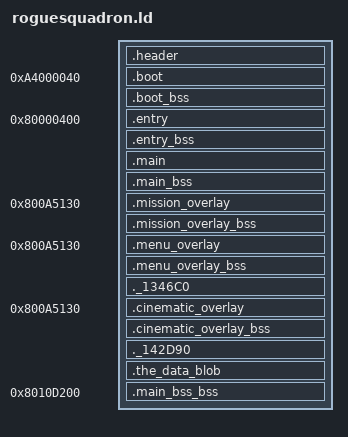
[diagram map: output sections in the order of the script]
SECTIONS
{
    __romPos = 0;
    header_ROM_START = __romPos;
    header_VRAM = ADDR(.header);
    .header : AT(header_ROM_START) SUBALIGN(16)
    {
        FILL(0x00000000);
        header_DATA_START = .;
        build/asm/header.o(.data);
        header_DATA_END = .;
        header_DATA_SIZE = ABSOLUTE(header_DATA_END - header_DATA_START);
    }
    __romPos += SIZEOF(.header);
    header_ROM_END = __romPos;
    header_VRAM_END = .;

    boot_ROM_START = __romPos;
    boot_VRAM = ADDR(.boot);
    .boot 0xA4000040 : AT(boot_ROM_START) SUBALIGN(16)
    {
        FILL(0x00000000);
        boot_TEXT_START = .;
        build/asm/ipl3_entry.o(.text);
        . = ALIGN(., 16);
        boot_TEXT_END = .;
        boot_TEXT_SIZE = ABSOLUTE(boot_TEXT_END - boot_TEXT_START);
        boot_DATA_START = .;
        build/asm/ipl3_entry.o(.data);
        build/assets/ipl3_font.o(.data);
        . = ALIGN(., 16);
        boot_DATA_END = .;
        boot_DATA_SIZE = ABSOLUTE(boot_DATA_END - boot_DATA_START);
        boot_RODATA_START = .;
        build/asm/ipl3_entry.o(.rodata);
        . = ALIGN(., 16);
        boot_RODATA_END = .;
        boot_RODATA_SIZE = ABSOLUTE(boot_RODATA_END - boot_RODATA_START);
    }
    boot_bss_VRAM = ADDR(.boot_bss);
    .boot_bss (NOLOAD) : SUBALIGN(16)
    {
        FILL(0x00000000);
        boot_BSS_START = .;
        build/asm/ipl3_entry.o(.bss);
        . = ALIGN(., 16);
        boot_BSS_END = .;
        boot_BSS_SIZE = ABSOLUTE(boot_BSS_END - boot_BSS_START);
    }
    __romPos += SIZEOF(.boot);
    __romPos = ALIGN(__romPos, 16);
    . = ALIGN(., 16);
    boot_ROM_END = __romPos;
    boot_VRAM_END = .;

    entry_ROM_START = __romPos;
    entry_VRAM = ADDR(.entry);
    .entry 0x80000400 : AT(entry_ROM_START) SUBALIGN(16)
    {
        FILL(0x00000000);
        entry_TEXT_START = .;
        build/asm/entry_point.o(.text);
        . = ALIGN(., 16);
        entry_TEXT_END = .;
        entry_TEXT_SIZE = ABSOLUTE(entry_TEXT_END - entry_TEXT_START);
        entry_DATA_START = .;
        build/asm/entry_point.o(.data);
        . = ALIGN(., 16);
        entry_DATA_END = .;
        entry_DATA_SIZE = ABSOLUTE(entry_DATA_END - entry_DATA_START);
        entry_RODATA_START = .;
        build/asm/entry_point.o(.rodata);
        . = ALIGN(., 16);
        entry_RODATA_END = .;
        entry_RODATA_SIZE = ABSOLUTE(entry_RODATA_END - entry_RODATA_START);
    }
    entry_bss_VRAM = ADDR(.entry_bss);
    .entry_bss (NOLOAD) : SUBALIGN(16)
    {
        FILL(0x00000000);
        entry_BSS_START = .;
        build/asm/entry_point.o(.bss);
        . = ALIGN(., 16);
        entry_BSS_END = .;
        entry_BSS_SIZE = ABSOLUTE(entry_BSS_END - entry_BSS_START);
    }
    __romPos += SIZEOF(.entry);
    __romPos = ALIGN(__romPos, 16);
    . = ALIGN(., 16);
    entry_ROM_END = __romPos;
    entry_VRAM_END = .;

    main_ROM_START = __romPos;
    main_VRAM = ADDR(.main);
    .main entry_VRAM_END : AT(main_ROM_START) SUBALIGN(16)
    {
        FILL(0x00000000);
        main_TEXT_START = .;
        build/asm/main/01720.o(.text);
        build/asm/main/033C0.o(.text);
        build/asm/main/03F80.o(.text);
        build/asm/main/04030.o(.text);
        build/asm/main/04080.o(.text);
        build/asm/main/05F80.o(.text);
        build/asm/main/06170.o(.text);
        build/asm/main/06560.o(.text);
        build/asm/main/07800.o(.text);
        build/asm/main/07F80.o(.text);
        build/asm/main/080E0.o(.text);
        build/asm/main/08120.o(.text);
        build/asm/main/08510.o(.text);
        build/asm/main/192E0.o(.text);
        build/asm/main/1A410.o(.text);
        build/asm/main/1D000.o(.text);
        build/asm/main/24570.o(.text);
        build/asm/main/24D30.o(.text);
        build/asm/main/25480.o(.text);
        build/asm/data/main/gspF3DEXMainText.o(.text);
        build/src/zlib/adler32.o(.text);
        build/src/zlib/inflate.o(.text);
        build/src/zlib/infblock.o(.text);
        build/src/zlib/infcodes.o(.text);
        build/src/zlib/inffast.o(.text);
        build/src/zlib/inftrees.o(.text);
        build/src/zlib/infutil.o(.text);
        build/src/zlib/zutil.o(.text);
        build/src/libultra/io/aisetfreq.o(.text);
        build/src/libultra/io/aisetnextbuf.o(.text);
        build/src/libultra/io/ai.o(.text);
        build/asm/libultra/libc/bcmp.o(.text);
        build/asm/libultra/libc/bzero.o(.text);
        build/src/libultra/io/conteeplongread.o(.text);
        build/src/libultra/io/conteeplongwrite.o(.text);
        build/src/libultra/io/conteepprobe.o(.text);
        build/src/libultra/io/conteepread.o(.text);
        build/src/libultra/io/conteepwrite.o(.text);
        build/src/libultra/io/contquery.o(.text);
        build/src/libultra/io/contreaddata.o(.text);
        build/src/libultra/io/controller.o(.text);
        build/src/libultra/gu/cosf.o(.text);
        build/src/libultra/os/createmesgqueue.o(.text);
        build/src/libultra/os/createthread.o(.text);
        build/src/libultra/os/destroythread.o(.text);
        build/src/libultra/io/dpctr.o(.text);
        build/src/libultra/io/dpsetstat.o(.text);
        build/asm/libultra/os/exceptasm.o(.text);
        build/src/libultra/os/gettime.o(.text);
        build/asm/libultra/os/getcount.o(.text);
        build/src/libultra/os/initialize.o(.text);
        build/asm/libultra/os/getsr.o(.text);
        build/asm/libultra/os/interrupt.o(.text);
        build/asm/libultra/os/invaldcache.o(.text);
        build/asm/libultra/os/invalicache.o(.text);
        build/src/libultra/os/jammesg.o(.text);
        build/src/libultra/io/leointerrupt.o(.text);
        build/src/libultra/io/epirawdma.o(.text);
        build/src/libultra/io/leodiskinit.o(.text);
        build/src/libultra/libc/ll.o(.text);
        build/asm/libultra/os/maptlbrdb.o(.text);
        build/src/libultra/io/motor.o(.text);
        build/src/libultra/io/contramread.o(.text);
        build/src/libultra/io/contramwrite.o(.text);
        build/src/libultra/io/crc.o(.text);
        build/src/libultra/gu/mtxcatl.o(.text);
        . += 0xA0;
        build/src/libultra/gu/mtxcatf.o(.text);
        build/src/libultra/gu/mtxutil.o(.text);
        build/src/libultra/gu/perspective.o(.text);
        build/src/libultra/io/pfsallocatefile.o(.text);
        build/src/libultra/io/contpfs.o(.text);
        build/src/libultra/io/pfsdeletefile.o(.text);
        build/src/libultra/io/pfsfreeblocks.o(.text);
        build/src/libultra/io/pfsgetstatus.o(.text);
        build/src/libultra/io/pfsinitpak.o(.text);
        build/src/libultra/io/pfschecker.o(.text);
        build/src/libultra/io/pfsisplug.o(.text);
        build/src/libultra/io/pfsreadwritefile.o(.text);
        build/src/libultra/io/pfsrepairid.o(.text);
        build/src/libultra/io/pfssearchfile.o(.text);
        build/src/libultra/io/pidma.o(.text);
        build/src/libultra/io/pigetcmdq.o(.text);
        build/src/libultra/io/pimgr.o(.text);
        build/src/libultra/io/cartrominit.o(.text);
        build/src/libultra/io/devmgr.o(.text);
        build/src/libultra/io/epirawread.o(.text);
        build/src/libultra/io/epirawwrite.o(.text);
        build/src/libultra/os/getthreadpri.o(.text);
        build/src/libultra/io/piacs.o(.text);
        build/src/libultra/io/pirawdma.o(.text);
        build/src/libultra/io/pirawread.o(.text);
        build/src/libultra/os/recvmesg.o(.text);
        build/src/libultra/os/resetglobalintmask.o(.text);
        build/src/libultra/gu/scale.o(.text);
        build/src/libultra/os/sendmesg.o(.text);
        build/src/libultra/os/seteventmesg.o(.text);
        build/asm/libultra/os/setfpccsr.o(.text);
        build/src/libultra/os/setglobalintmask.o(.text);
        build/asm/libultra/os/setintmask.o(.text);
        build/asm/libultra/os/setsr.o(.text);
        build/src/libultra/os/setthreadpri.o(.text);
        build/src/libultra/os/settimer.o(.text);
        build/src/libultra/io/siacs.o(.text);
        build/src/libultra/gu/sinf.o(.text);
        build/src/libultra/io/sirawdma.o(.text);
        build/src/libultra/io/si.o(.text);
        build/src/libultra/io/sirawread.o(.text);
        build/src/libultra/io/sirawwrite.o(.text);
        build/src/libultra/libc/sprintf.o(.text);
        build/src/libultra/io/sptask.o(.text);
        build/asm/libultra/libc/bcopy.o(.text);
        build/src/libultra/io/sp.o(.text);
        build/src/libultra/io/sprawdma.o(.text);
        build/src/libultra/io/spsetpc.o(.text);
        build/src/libultra/io/spsetstat.o(.text);
        build/src/libultra/io/sptaskyield.o(.text);
        build/src/libultra/io/sptaskyielded.o(.text);
        build/src/libultra/io/spgetstat.o(.text);
        build/src/libultra/os/startthread.o(.text);
        build/src/libultra/os/stopthread.o(.text);
        build/src/libultra/libc/string.o(.text);
        build/src/libultra/os/thread.o(.text);
        build/src/libultra/os/timerintr.o(.text);
        build/asm/libultra/os/setcompare.o(.text);
        build/src/libultra/io/viblack.o(.text);
        build/src/libultra/io/vi.o(.text);
        build/src/libultra/io/vigetfield.o(.text);
        build/src/libultra/io/vimgr.o(.text);
        build/src/libultra/io/vigetcurrcontext.o(.text);
        build/src/libultra/os/virtualtophysical.o(.text);
        build/asm/libultra/os/probetlb.o(.text);
        build/src/libultra/io/visetevent.o(.text);
        build/src/libultra/io/visetmode.o(.text);
        build/src/libultra/io/visetspecial.o(.text);
        build/src/libultra/io/viswapbuf.o(.text);
        build/src/libultra/io/viswapcontext.o(.text);
        build/asm/libultra/os/writebackdcache.o(.text);
        build/asm/libultra/os/writebackdcacheall.o(.text);
        build/src/libultra/libc/xprintf.o(.text);
        build/src/libultra/libc/xldtob.o(.text);
        build/src/libultra/libc/ldiv.o(.text);
        build/src/libultra/libc/xlitob.o(.text);
        build/src/libultra/os/yieldthread.o(.text);
        build/asm/main/3EB20.o(.text);
        build/asm/main/3EBA0.o(.text);
        build/asm/main/3F160.o(.text);
        build/asm/main/40F10.o(.text);
        build/asm/main/42AF0.o(.text);
        build/asm/main/463D0.o(.text);
        build/asm/main/47220.o(.text);
        build/asm/main/4A300.o(.text);
        build/asm/main/4D900.o(.text);
        build/asm/main/544B0.o(.text);
        build/asm/main/55250.o(.text);
        build/asm/main/55AF0.o(.text);
        build/asm/main/561F0.o(.text);
        build/asm/main/562A0.o(.text);
        build/asm/main/56630.o(.text);
        build/asm/main/56F50.o(.text);
        build/asm/main/5A750.o(.text);
        build/asm/main/5AD20.o(.text);
        build/asm/main/5D220.o(.text);
        build/asm/main/5FA70.o(.text);
        build/asm/main/61FC0.o(.text);
        build/asm/main/64EA0.o(.text);
        build/asm/main/65540.o(.text);
        build/asm/main/66660.o(.text);
        build/asm/main/66FB0.o(.text);
        build/asm/main/68990.o(.text);
        build/asm/main/6A6F0.o(.text);
        build/asm/main/6B8B0.o(.text);
        build/asm/main/6C310.o(.text);
        build/asm/main/6E500.o(.text);
        build/asm/main/700B0.o(.text);
        build/asm/main/738F0.o(.text);
        build/asm/main/79E80.o(.text);
        build/asm/main/7A8E0.o(.text);
        build/asm/main/7ACF0.o(.text);
        build/asm/main/7B470.o(.text);
        build/asm/main/7CEA0.o(.text);
        build/asm/main/82E70.o(.text);
        build/asm/data/main/rspbootText.o(.text);
        build/asm/main/832A0.o(.text);
        build/asm/main/94A80.o(.text);
        build/asm/main/94F50.o(.text);
        build/asm/main/97D20.o(.text);
        build/asm/main/98960.o(.text);
        build/asm/main/9A850.o(.text);
        build/asm/data/main/aspMainText.o(.text);
        build/asm/main/9BB60.o(.text);
        build/asm/main/9CED0.o(.text);
        build/asm/main/9E3D0.o(.text);
        . = ALIGN(., 16);
        main_TEXT_END = .;
        main_TEXT_SIZE = ABSOLUTE(main_TEXT_END - main_TEXT_START);
        main_DATA_START = .;
        build/asm/data/main/04070.data.o(.data);
        build/asm/data/main/38160.data.o(.data);
        build/asm/data/main/381B0.data.o(.data);
        build/asm/data/main/381C0.data.o(.data);
        build/asm/data/main/38220.data.o(.data);
        build/asm/data/main/38230.data.o(.data);
        build/asm/data/main/38240.data.o(.data);
        build/asm/data/main/38250.data.o(.data);
        build/asm/data/main/383C0.data.o(.data);
        build/asm/data/main/39460.data.o(.data);
        build/asm/data/main/394E0.data.o(.data);
        build/asm/data/main/398F0.data.o(.data);
        build/asm/data/main/gspF3DEXMainData.o(.data);
        build/asm/data/zlib/infblock.data.o(.data);
        build/src/zlib/infcodes.o(.data);
        build/src/zlib/inffast.o(.data);
        build/asm/data/zlib/inftrees.data.o(.data);
        build/asm/data/zlib/infutil.data.o(.data);
        build/asm/data/zlib/zutil.data.o(.data);
        build/src/libultra/io/aisetfreq.o(.data);
        build/src/libultra/io/aisetnextbuf.o(.data);
        build/src/libultra/io/ai.o(.data);
        build/asm/libultra/libc/bcmp.o(.data);
        build/asm/libultra/libc/bzero.o(.data);
        build/src/libultra/io/conteeplongread.o(.data);
        build/src/libultra/io/conteeplongwrite.o(.data);
        build/src/libultra/io/conteepprobe.o(.data);
        build/src/libultra/io/conteepread.o(.data);
        build/src/libultra/io/conteepwrite.o(.data);
        build/src/libultra/io/contquery.o(.data);
        build/src/libultra/io/contreaddata.o(.data);
        build/src/libultra/io/controller.o(.data);
        build/src/libultra/gu/cosf.o(.data);
        build/src/libultra/os/createmesgqueue.o(.data);
        build/src/libultra/os/createthread.o(.data);
        build/src/libultra/os/destroythread.o(.data);
        build/src/libultra/io/dpctr.o(.data);
        build/src/libultra/io/dpsetstat.o(.data);
        build/asm/libultra/os/exceptasm.o(.data);
        build/src/libultra/os/gettime.o(.data);
        build/asm/libultra/os/getcount.o(.data);
        build/src/libultra/os/initialize.o(.data);
        build/asm/libultra/os/getsr.o(.data);
        build/asm/libultra/os/interrupt.o(.data);
        build/asm/libultra/os/invaldcache.o(.data);
        build/asm/libultra/os/invalicache.o(.data);
        build/src/libultra/os/jammesg.o(.data);
        build/src/libultra/io/leointerrupt.o(.data);
        build/src/libultra/io/epirawdma.o(.data);
        build/src/libultra/io/leodiskinit.o(.data);
        build/src/libultra/libc/ll.o(.data);
        build/asm/libultra/os/maptlbrdb.o(.data);
        build/src/libultra/io/motor.o(.data);
        build/src/libultra/io/contramread.o(.data);
        build/src/libultra/io/contramwrite.o(.data);
        build/src/libultra/io/crc.o(.data);
        build/src/libultra/gu/mtxcatl.o(.data);
        build/src/libultra/gu/mtxcatf.o(.data);
        build/src/libultra/gu/mtxutil.o(.data);
        build/src/libultra/gu/perspective.o(.data);
        build/src/libultra/io/pfsallocatefile.o(.data);
        build/src/libultra/io/contpfs.o(.data);
        build/src/libultra/io/pfsdeletefile.o(.data);
        build/src/libultra/io/pfsfreeblocks.o(.data);
        build/src/libultra/io/pfsgetstatus.o(.data);
        build/src/libultra/io/pfsinitpak.o(.data);
        build/src/libultra/io/pfschecker.o(.data);
        build/src/libultra/io/pfsisplug.o(.data);
        build/src/libultra/io/pfsreadwritefile.o(.data);
        build/src/libultra/io/pfsrepairid.o(.data);
        build/src/libultra/io/pfssearchfile.o(.data);
        build/src/libultra/io/pidma.o(.data);
        build/src/libultra/io/pigetcmdq.o(.data);
        build/src/libultra/io/pimgr.o(.data);
        build/src/libultra/io/cartrominit.o(.data);
        build/src/libultra/io/devmgr.o(.data);
        build/src/libultra/io/epirawread.o(.data);
        build/src/libultra/io/epirawwrite.o(.data);
        build/src/libultra/os/getthreadpri.o(.data);
        build/src/libultra/io/piacs.o(.data);
        build/src/libultra/io/pirawdma.o(.data);
        build/src/libultra/io/pirawread.o(.data);
        build/src/libultra/os/recvmesg.o(.data);
        build/src/libultra/os/resetglobalintmask.o(.data);
        build/src/libultra/gu/scale.o(.data);
        build/src/libultra/os/sendmesg.o(.data);
        build/src/libultra/os/seteventmesg.o(.data);
        build/asm/libultra/os/setfpccsr.o(.data);
        build/src/libultra/os/setglobalintmask.o(.data);
        build/asm/libultra/os/setintmask.o(.data);
        build/asm/libultra/os/setsr.o(.data);
        build/src/libultra/os/setthreadpri.o(.data);
        build/src/libultra/os/settimer.o(.data);
        build/src/libultra/io/siacs.o(.data);
        build/src/libultra/gu/sinf.o(.data);
        build/src/libultra/io/sirawdma.o(.data);
        build/src/libultra/io/si.o(.data);
        build/src/libultra/io/sirawread.o(.data);
        build/src/libultra/io/sirawwrite.o(.data);
        build/src/libultra/libc/sprintf.o(.data);
        build/src/libultra/io/sptask.o(.data);
        build/asm/libultra/libc/bcopy.o(.data);
        build/src/libultra/io/sp.o(.data);
        build/src/libultra/io/sprawdma.o(.data);
        build/src/libultra/io/spsetpc.o(.data);
        build/src/libultra/io/spsetstat.o(.data);
        build/src/libultra/io/sptaskyield.o(.data);
        build/src/libultra/io/sptaskyielded.o(.data);
        build/src/libultra/io/spgetstat.o(.data);
        build/src/libultra/os/startthread.o(.data);
        build/src/libultra/os/stopthread.o(.data);
        build/src/libultra/libc/string.o(.data);
        build/src/libultra/os/thread.o(.data);
        build/src/libultra/os/timerintr.o(.data);
        build/asm/libultra/os/setcompare.o(.data);
        build/src/libultra/io/viblack.o(.data);
        build/src/libultra/io/vi.o(.data);
        build/src/libultra/io/vigetfield.o(.data);
        build/src/libultra/io/vimgr.o(.data);
        build/src/libultra/io/vigetcurrcontext.o(.data);
        build/src/libultra/os/virtualtophysical.o(.data);
        build/asm/libultra/os/probetlb.o(.data);
        build/src/libultra/io/visetevent.o(.data);
        build/src/libultra/io/visetmode.o(.data);
        build/src/libultra/io/visetspecial.o(.data);
        build/src/libultra/io/viswapbuf.o(.data);
        build/src/libultra/io/viswapcontext.o(.data);
        build/asm/libultra/os/writebackdcache.o(.data);
        build/asm/libultra/os/writebackdcacheall.o(.data);
        build/src/libultra/vimodes/vimodempallan1.o(.data);
        build/src/libultra/vimodes/vimodentsclan1.o(.data);
        build/src/libultra/vimodes/vimodepallan1.o(.data);
        build/src/libultra/io/vitbl.o(.data);
        build/src/libultra/libc/xprintf.o(.data);
        build/src/libultra/libc/xldtob.o(.data);
        build/src/libultra/libc/ldiv.o(.data);
        build/src/libultra/libc/xlitob.o(.data);
        build/src/libultra/os/yieldthread.o(.data);
        build/asm/main/3EB20.o(.data);
        build/asm/main/3EBA0.o(.data);
        build/asm/main/3F160.o(.data);
        build/asm/main/40F10.o(.data);
        build/asm/main/42AF0.o(.data);
        build/asm/main/463D0.o(.data);
        build/asm/main/47220.o(.data);
        build/asm/main/4A300.o(.data);
        build/asm/main/4D900.o(.data);
        build/asm/main/544B0.o(.data);
        build/asm/main/55250.o(.data);
        build/asm/main/55AF0.o(.data);
        build/asm/main/561F0.o(.data);
        build/asm/main/562A0.o(.data);
        build/asm/main/56630.o(.data);
        build/asm/main/56F50.o(.data);
        build/asm/main/5A750.o(.data);
        build/asm/main/5AD20.o(.data);
        build/asm/main/5D220.o(.data);
        build/asm/main/5FA70.o(.data);
        build/asm/main/61FC0.o(.data);
        build/asm/main/64EA0.o(.data);
        build/asm/main/65540.o(.data);
        build/asm/main/66660.o(.data);
        build/asm/main/66FB0.o(.data);
        build/asm/main/68990.o(.data);
        build/asm/main/6A6F0.o(.data);
        build/asm/main/6B8B0.o(.data);
        build/asm/main/6C310.o(.data);
        build/asm/main/6E500.o(.data);
        build/asm/main/700B0.o(.data);
        build/asm/main/738F0.o(.data);
        build/asm/main/79E80.o(.data);
        build/asm/main/7A8E0.o(.data);
        build/asm/main/7ACF0.o(.data);
        build/asm/main/7B470.o(.data);
        build/asm/main/7CEA0.o(.data);
        build/asm/main/82E70.o(.data);
        build/asm/data/main/rspbootText.o(.data);
        build/asm/main/832A0.o(.data);
        build/asm/main/94A80.o(.data);
        build/asm/main/94F50.o(.data);
        build/asm/main/97D20.o(.data);
        build/asm/main/98960.o(.data);
        build/asm/main/9A850.o(.data);
        build/asm/data/main/aspMainText.o(.data);
        build/asm/main/9BB60.o(.data);
        build/asm/main/9CED0.o(.data);
        build/asm/main/9E3D0.o(.data);
        build/asm/main/01720.o(.data);
        build/asm/main/033C0.o(.data);
        build/asm/main/03F80.o(.data);
        build/asm/main/04030.o(.data);
        build/asm/main/04080.o(.data);
        build/asm/main/05F80.o(.data);
        build/asm/main/06170.o(.data);
        build/asm/main/06560.o(.data);
        build/asm/main/07800.o(.data);
        build/asm/main/07F80.o(.data);
        build/asm/main/080E0.o(.data);
        build/asm/main/08120.o(.data);
        build/asm/main/08510.o(.data);
        build/asm/main/192E0.o(.data);
        build/asm/main/1A410.o(.data);
        build/asm/main/1D000.o(.data);
        build/asm/main/24570.o(.data);
        build/asm/main/24D30.o(.data);
        build/asm/main/25480.o(.data);
        build/asm/data/main/gspF3DEXMainText.o(.data);
        build/src/zlib/adler32.o(.data);
        build/src/zlib/inflate.o(.data);
        build/asm/data/main/aspMainData.o(.data);
        . = ALIGN(., 16);
        main_DATA_END = .;
        main_DATA_SIZE = ABSOLUTE(main_DATA_END - main_DATA_START);
        main_RODATA_START = .;
        build/asm/data/main/01040.rodata.o(.rodata);
        build/asm/data/main/01050.rodata.o(.rodata);
        build/asm/data/main/01060.rodata.o(.rodata);
        build/asm/data/main/01070.rodata.o(.rodata);
        build/asm/data/main/01080.rodata.o(.rodata);
        build/asm/data/main/01100.rodata.o(.rodata);
        build/asm/data/main/01120.rodata.o(.rodata);
        build/asm/data/main/013D0.rodata.o(.rodata);
        build/asm/data/main/013F0.rodata.o(.rodata);
        build/asm/data/main/01410.rodata.o(.rodata);
        build/asm/data/main/01590.rodata.o(.rodata);
        build/asm/data/main/01600.rodata.o(.rodata);
        build/src/zlib/inflate.o(.rodata);
        build/src/zlib/infblock.o(.rodata);
        build/src/zlib/infcodes.o(.rodata);
        build/src/zlib/inffast.o(.rodata);
        build/src/zlib/inftrees.o(.rodata);
        build/src/zlib/infutil.o(.rodata);
        build/src/zlib/zutil.o(.rodata);
        build/src/libultra/io/aisetfreq.o(.rodata);
        build/src/libultra/io/aisetnextbuf.o(.rodata);
        build/src/libultra/io/ai.o(.rodata);
        build/asm/libultra/libc/bcmp.o(.rodata);
        build/asm/libultra/libc/bzero.o(.rodata);
        build/src/libultra/io/conteeplongread.o(.rodata);
        build/src/libultra/io/conteeplongwrite.o(.rodata);
        build/src/libultra/io/conteepprobe.o(.rodata);
        build/src/libultra/io/conteepread.o(.rodata);
        build/src/libultra/io/conteepwrite.o(.rodata);
        build/src/libultra/io/contquery.o(.rodata);
        build/src/libultra/io/contreaddata.o(.rodata);
        build/src/libultra/io/controller.o(.rodata);
        build/asm/main/01720.o(.rodata);
        build/asm/main/033C0.o(.rodata);
        build/asm/main/03F80.o(.rodata);
        build/asm/main/04030.o(.rodata);
        build/asm/main/04080.o(.rodata);
        build/asm/main/05F80.o(.rodata);
        build/asm/main/06170.o(.rodata);
        build/asm/main/06560.o(.rodata);
        build/asm/main/07800.o(.rodata);
        build/asm/main/07F80.o(.rodata);
        build/asm/main/080E0.o(.rodata);
        build/asm/main/08120.o(.rodata);
        build/asm/main/08510.o(.rodata);
        build/asm/main/192E0.o(.rodata);
        build/asm/main/1A410.o(.rodata);
        build/asm/main/1D000.o(.rodata);
        build/asm/main/24570.o(.rodata);
        build/asm/main/24D30.o(.rodata);
        build/asm/main/25480.o(.rodata);
        build/asm/data/main/gspF3DEXMainText.o(.rodata);
        build/src/zlib/adler32.o(.rodata);
        build/src/libultra/gu/cosf.o(.rodata);
        build/src/libultra/os/createmesgqueue.o(.rodata);
        build/src/libultra/os/createthread.o(.rodata);
        build/src/libultra/os/destroythread.o(.rodata);
        build/src/libultra/io/dpctr.o(.rodata);
        build/src/libultra/io/dpsetstat.o(.rodata);
        build/asm/libultra/os/exceptasm.o(.rodata);
        build/src/libultra/os/gettime.o(.rodata);
        build/asm/libultra/os/getcount.o(.rodata);
        build/src/libultra/os/initialize.o(.rodata);
        build/asm/libultra/os/getsr.o(.rodata);
        build/asm/libultra/os/interrupt.o(.rodata);
        build/asm/libultra/os/invaldcache.o(.rodata);
        build/asm/libultra/os/invalicache.o(.rodata);
        build/src/libultra/os/jammesg.o(.rodata);
        build/src/libultra/io/leointerrupt.o(.rodata);
        build/src/libultra/io/epirawdma.o(.rodata);
        build/src/libultra/io/leodiskinit.o(.rodata);
        build/src/libultra/libc/ll.o(.rodata);
        build/asm/libultra/os/maptlbrdb.o(.rodata);
        build/src/libultra/io/motor.o(.rodata);
        build/src/libultra/io/contramread.o(.rodata);
        build/src/libultra/io/contramwrite.o(.rodata);
        build/src/libultra/io/crc.o(.rodata);
        build/src/libultra/gu/mtxcatl.o(.rodata);
        build/src/libultra/gu/mtxcatf.o(.rodata);
        build/src/libultra/gu/mtxutil.o(.rodata);
        build/src/libultra/gu/libm_vals.o(.rodata);
        build/src/libultra/gu/perspective.o(.rodata);
        build/src/libultra/io/pfsallocatefile.o(.rodata);
        build/src/libultra/io/contpfs.o(.rodata);
        build/src/libultra/io/pfsdeletefile.o(.rodata);
        build/src/libultra/io/pfsfreeblocks.o(.rodata);
        build/src/libultra/io/pfsgetstatus.o(.rodata);
        build/src/libultra/io/pfsinitpak.o(.rodata);
        build/src/libultra/io/pfschecker.o(.rodata);
        build/src/libultra/io/pfsisplug.o(.rodata);
        build/src/libultra/io/pfsreadwritefile.o(.rodata);
        build/src/libultra/io/pfsrepairid.o(.rodata);
        build/src/libultra/io/pfssearchfile.o(.rodata);
        build/src/libultra/io/pidma.o(.rodata);
        build/src/libultra/io/pigetcmdq.o(.rodata);
        build/src/libultra/io/pimgr.o(.rodata);
        build/src/libultra/io/cartrominit.o(.rodata);
        build/src/libultra/io/devmgr.o(.rodata);
        build/src/libultra/io/epirawread.o(.rodata);
        build/src/libultra/io/epirawwrite.o(.rodata);
        build/src/libultra/os/getthreadpri.o(.rodata);
        build/src/libultra/io/piacs.o(.rodata);
        build/src/libultra/io/pirawdma.o(.rodata);
        build/src/libultra/io/pirawread.o(.rodata);
        build/src/libultra/os/recvmesg.o(.rodata);
        build/src/libultra/os/resetglobalintmask.o(.rodata);
        build/src/libultra/gu/scale.o(.rodata);
        build/src/libultra/os/sendmesg.o(.rodata);
        build/src/libultra/os/seteventmesg.o(.rodata);
        build/asm/libultra/os/setfpccsr.o(.rodata);
        build/src/libultra/os/setglobalintmask.o(.rodata);
        build/asm/libultra/os/setintmask.o(.rodata);
        build/asm/libultra/os/setsr.o(.rodata);
        build/src/libultra/os/setthreadpri.o(.rodata);
        build/src/libultra/os/settimer.o(.rodata);
        build/src/libultra/io/siacs.o(.rodata);
        build/src/libultra/gu/sinf.o(.rodata);
        build/src/libultra/io/sirawdma.o(.rodata);
        build/src/libultra/io/si.o(.rodata);
        build/src/libultra/io/sirawread.o(.rodata);
        build/src/libultra/io/sirawwrite.o(.rodata);
        build/src/libultra/libc/sprintf.o(.rodata);
        build/src/libultra/io/sptask.o(.rodata);
        build/asm/libultra/libc/bcopy.o(.rodata);
        build/src/libultra/io/sp.o(.rodata);
        build/src/libultra/io/sprawdma.o(.rodata);
        build/src/libultra/io/spsetpc.o(.rodata);
        build/src/libultra/io/spsetstat.o(.rodata);
        build/src/libultra/io/sptaskyield.o(.rodata);
        build/src/libultra/io/sptaskyielded.o(.rodata);
        build/src/libultra/io/spgetstat.o(.rodata);
        build/src/libultra/os/startthread.o(.rodata);
        build/src/libultra/os/stopthread.o(.rodata);
        build/src/libultra/libc/string.o(.rodata);
        build/src/libultra/os/thread.o(.rodata);
        build/src/libultra/os/timerintr.o(.rodata);
        build/asm/libultra/os/setcompare.o(.rodata);
        build/src/libultra/io/viblack.o(.rodata);
        build/src/libultra/io/vi.o(.rodata);
        build/src/libultra/io/vigetfield.o(.rodata);
        build/src/libultra/io/vimgr.o(.rodata);
        build/src/libultra/io/vigetcurrcontext.o(.rodata);
        build/src/libultra/os/virtualtophysical.o(.rodata);
        build/asm/libultra/os/probetlb.o(.rodata);
        build/src/libultra/io/visetevent.o(.rodata);
        build/src/libultra/io/visetmode.o(.rodata);
        build/src/libultra/io/visetspecial.o(.rodata);
        build/src/libultra/io/viswapbuf.o(.rodata);
        build/src/libultra/io/viswapcontext.o(.rodata);
        build/asm/libultra/os/writebackdcache.o(.rodata);
        build/asm/libultra/os/writebackdcacheall.o(.rodata);
        build/src/libultra/libc/xprintf.o(.rodata);
        build/src/libultra/libc/xldtob.o(.rodata);
        build/src/libultra/libc/ldiv.o(.rodata);
        build/src/libultra/libc/xlitob.o(.rodata);
        build/src/libultra/os/yieldthread.o(.rodata);
        build/asm/main/3EB20.o(.rodata);
        build/asm/main/3EBA0.o(.rodata);
        build/asm/main/3F160.o(.rodata);
        build/asm/main/40F10.o(.rodata);
        build/asm/main/42AF0.o(.rodata);
        build/asm/main/463D0.o(.rodata);
        build/asm/main/47220.o(.rodata);
        build/asm/main/4A300.o(.rodata);
        build/asm/main/4D900.o(.rodata);
        build/asm/main/544B0.o(.rodata);
        build/asm/main/55250.o(.rodata);
        build/asm/main/55AF0.o(.rodata);
        build/asm/main/561F0.o(.rodata);
        build/asm/main/562A0.o(.rodata);
        build/asm/main/56630.o(.rodata);
        build/asm/main/56F50.o(.rodata);
        build/asm/main/5A750.o(.rodata);
        build/asm/main/5AD20.o(.rodata);
        build/asm/main/5D220.o(.rodata);
        build/asm/main/5FA70.o(.rodata);
        build/asm/main/61FC0.o(.rodata);
        build/asm/main/64EA0.o(.rodata);
        build/asm/main/65540.o(.rodata);
        build/asm/main/66660.o(.rodata);
        build/asm/main/66FB0.o(.rodata);
        build/asm/main/68990.o(.rodata);
        build/asm/main/6A6F0.o(.rodata);
        build/asm/main/6B8B0.o(.rodata);
        build/asm/main/6C310.o(.rodata);
        build/asm/main/6E500.o(.rodata);
        build/asm/main/700B0.o(.rodata);
        build/asm/main/738F0.o(.rodata);
        build/asm/main/79E80.o(.rodata);
        build/asm/main/7A8E0.o(.rodata);
        build/asm/main/7ACF0.o(.rodata);
        build/asm/main/7B470.o(.rodata);
        build/asm/main/7CEA0.o(.rodata);
        build/asm/main/82E70.o(.rodata);
        build/asm/data/main/rspbootText.o(.rodata);
        build/asm/main/832A0.o(.rodata);
        build/asm/main/94A80.o(.rodata);
        build/asm/main/94F50.o(.rodata);
        build/asm/main/97D20.o(.rodata);
        build/asm/main/98960.o(.rodata);
        build/asm/main/9A850.o(.rodata);
        build/asm/data/main/aspMainText.o(.rodata);
        build/asm/main/9BB60.o(.rodata);
        build/asm/main/9CED0.o(.rodata);
        build/asm/main/9E3D0.o(.rodata);
        build/asm/data/main/3AFE0.rodata.o(.rodata);
        build/asm/data/main/3B0D0.rodata.o(.rodata);
        build/asm/data/main/3B210.rodata.o(.rodata);
        build/asm/data/main/3B240.rodata.o(.rodata);
        build/asm/data/main/3B3E0.rodata.o(.rodata);
        build/asm/data/main/3B420.rodata.o(.rodata);
        build/asm/data/main/3B4C0.rodata.o(.rodata);
        build/asm/data/main/3B4D0.rodata.o(.rodata);
        build/asm/data/main/3B7E0.rodata.o(.rodata);
        build/asm/data/main/3B8D0.rodata.o(.rodata);
        build/asm/data/main/3B920.rodata.o(.rodata);
        build/asm/data/main/3B9C0.rodata.o(.rodata);
        build/asm/data/main/3BE30.rodata.o(.rodata);
        build/asm/data/main/3BF00.rodata.o(.rodata);
        build/asm/data/main/3C010.rodata.o(.rodata);
        build/asm/data/main/3C430.rodata.o(.rodata);
        build/asm/data/main/3CE60.rodata.o(.rodata);
        build/asm/data/main/3CEE0.rodata.o(.rodata);
        build/asm/data/main/3D3D0.rodata.o(.rodata);
        build/asm/data/main/3D4D0.rodata.o(.rodata);
        build/asm/data/main/3D500.rodata.o(.rodata);
        build/asm/data/main/3D560.rodata.o(.rodata);
        build/asm/data/main/3D5D0.rodata.o(.rodata);
        build/asm/data/main/3D6F0.rodata.o(.rodata);
        build/asm/data/main/3D770.rodata.o(.rodata);
        build/asm/data/main/3DAF0.rodata.o(.rodata);
        build/asm/data/main/3E100.rodata.o(.rodata);
        build/asm/data/main/3E230.rodata.o(.rodata);
        build/asm/data/main/3EA70.rodata.o(.rodata);
        build/asm/data/main/3EAF0.rodata.o(.rodata);
        build/asm/data/main/3EB00.rodata.o(.rodata);
        build/asm/data/main/9E9D0.rodata.o(.rodata);
        build/asm/data/main/9EAC0.rodata.o(.rodata);
        build/asm/data/main/9EAD0.rodata.o(.rodata);
        build/asm/data/main/9EAE0.rodata.o(.rodata);
        build/asm/data/main/9F810.rodata.o(.rodata);
        build/asm/data/main/9F850.rodata.o(.rodata);
        build/asm/data/main/9F8A0.rodata.o(.rodata);
        build/asm/data/main/9F8B0.rodata.o(.rodata);
        build/asm/data/main/9F960.rodata.o(.rodata);
        build/asm/data/main/A0850.rodata.o(.rodata);
        build/asm/data/main/A08D0.rodata.o(.rodata);
        build/asm/data/main/A0BE0.rodata.o(.rodata);
        build/asm/data/main/A11D0.rodata.o(.rodata);
        build/asm/data/main/A1660.rodata.o(.rodata);
        build/asm/data/main/A1690.rodata.o(.rodata);
        build/asm/data/main/A1970.rodata.o(.rodata);
        build/asm/data/main/A1980.rodata.o(.rodata);
        build/asm/data/main/A1990.rodata.o(.rodata);
        build/asm/data/main/A1AD0.rodata.o(.rodata);
        build/asm/data/main/A1B50.rodata.o(.rodata);
        build/asm/data/main/A2360.rodata.o(.rodata);
        build/asm/data/main/A2380.rodata.o(.rodata);
        build/asm/data/main/A2390.rodata.o(.rodata);
        build/asm/data/main/A5D20.rodata.o(.rodata);
        . = ALIGN(., 16);
        main_RODATA_END = .;
        main_RODATA_SIZE = ABSOLUTE(main_RODATA_END - main_RODATA_START);
    }
    main_bss_VRAM = ADDR(.main_bss);
    .main_bss (NOLOAD) : SUBALIGN(16)
    {
        FILL(0x00000000);
        main_BSS_START = .;
        build/asm/main/01720.o(.bss);
        build/asm/main/033C0.o(.bss);
        build/asm/main/03F80.o(.bss);
        build/asm/main/04030.o(.bss);
        build/asm/main/04080.o(.bss);
        build/asm/main/05F80.o(.bss);
        build/asm/main/06170.o(.bss);
        build/asm/main/06560.o(.bss);
        build/asm/main/07800.o(.bss);
        build/asm/main/07F80.o(.bss);
        build/asm/main/080E0.o(.bss);
        build/asm/main/08120.o(.bss);
        build/asm/main/08510.o(.bss);
        build/asm/main/192E0.o(.bss);
        build/asm/main/1A410.o(.bss);
        build/asm/main/1D000.o(.bss);
        build/asm/main/24570.o(.bss);
        build/asm/main/24D30.o(.bss);
        build/asm/main/25480.o(.bss);
        build/asm/data/main/gspF3DEXMainText.o(.bss);
        build/src/zlib/adler32.o(.bss);
        build/src/zlib/inflate.o(.bss);
        build/src/zlib/infblock.o(.bss);
        build/src/zlib/infcodes.o(.bss);
        build/src/zlib/inffast.o(.bss);
        build/src/zlib/inftrees.o(.bss);
        build/src/zlib/infutil.o(.bss);
        build/src/zlib/zutil.o(.bss);
        build/src/libultra/io/aisetfreq.o(.bss);
        build/src/libultra/io/aisetnextbuf.o(.bss);
        build/src/libultra/io/ai.o(.bss);
        build/asm/libultra/libc/bcmp.o(.bss);
        build/asm/libultra/libc/bzero.o(.bss);
        build/src/libultra/io/conteeplongread.o(.bss);
        build/src/libultra/io/conteeplongwrite.o(.bss);
        build/src/libultra/io/conteepprobe.o(.bss);
        build/src/libultra/io/conteepread.o(.bss);
        build/src/libultra/io/conteepwrite.o(.bss);
        build/src/libultra/io/contquery.o(.bss);
        build/src/libultra/io/contreaddata.o(.bss);
        build/src/libultra/io/controller.o(.bss);
        build/src/libultra/gu/cosf.o(.bss);
        build/src/libultra/os/createmesgqueue.o(.bss);
        build/src/libultra/os/createthread.o(.bss);
        build/src/libultra/os/destroythread.o(.bss);
        build/src/libultra/io/dpctr.o(.bss);
        build/src/libultra/io/dpsetstat.o(.bss);
        build/asm/libultra/os/exceptasm.o(.bss);
        build/src/libultra/os/gettime.o(.bss);
        build/asm/libultra/os/getcount.o(.bss);
        build/src/libultra/os/initialize.o(.bss);
        build/asm/libultra/os/getsr.o(.bss);
        build/asm/libultra/os/interrupt.o(.bss);
        build/asm/libultra/os/invaldcache.o(.bss);
        build/asm/libultra/os/invalicache.o(.bss);
        build/src/libultra/os/jammesg.o(.bss);
        build/src/libultra/io/leointerrupt.o(.bss);
        build/src/libultra/io/epirawdma.o(.bss);
        build/src/libultra/io/leodiskinit.o(.bss);
        build/src/libultra/libc/ll.o(.bss);
        build/asm/libultra/os/maptlbrdb.o(.bss);
        build/src/libultra/io/motor.o(.bss);
        build/src/libultra/io/contramread.o(.bss);
        build/src/libultra/io/contramwrite.o(.bss);
        build/src/libultra/io/crc.o(.bss);
        build/src/libultra/gu/mtxcatl.o(.bss);
        build/src/libultra/gu/mtxcatf.o(.bss);
        build/src/libultra/gu/mtxutil.o(.bss);
        build/src/libultra/gu/perspective.o(.bss);
        build/src/libultra/io/pfsallocatefile.o(.bss);
        build/src/libultra/io/contpfs.o(.bss);
        build/src/libultra/io/pfsdeletefile.o(.bss);
        build/src/libultra/io/pfsfreeblocks.o(.bss);
        build/src/libultra/io/pfsgetstatus.o(.bss);
        build/src/libultra/io/pfsinitpak.o(.bss);
        build/src/libultra/io/pfschecker.o(.bss);
        build/src/libultra/io/pfsisplug.o(.bss);
        build/src/libultra/io/pfsreadwritefile.o(.bss);
        build/src/libultra/io/pfsrepairid.o(.bss);
        build/src/libultra/io/pfssearchfile.o(.bss);
        build/src/libultra/io/pidma.o(.bss);
        build/src/libultra/io/pigetcmdq.o(.bss);
        build/src/libultra/io/pimgr.o(.bss);
        build/src/libultra/io/cartrominit.o(.bss);
        build/src/libultra/io/devmgr.o(.bss);
        build/src/libultra/io/epirawread.o(.bss);
        build/src/libultra/io/epirawwrite.o(.bss);
        build/src/libultra/os/getthreadpri.o(.bss);
        build/src/libultra/io/piacs.o(.bss);
        build/src/libultra/io/pirawdma.o(.bss);
        build/src/libultra/io/pirawread.o(.bss);
        build/src/libultra/os/recvmesg.o(.bss);
        build/src/libultra/os/resetglobalintmask.o(.bss);
        build/src/libultra/gu/scale.o(.bss);
        build/src/libultra/os/sendmesg.o(.bss);
        build/src/libultra/os/seteventmesg.o(.bss);
        build/asm/libultra/os/setfpccsr.o(.bss);
        build/src/libultra/os/setglobalintmask.o(.bss);
        build/asm/libultra/os/setintmask.o(.bss);
        build/asm/libultra/os/setsr.o(.bss);
        build/src/libultra/os/setthreadpri.o(.bss);
        build/src/libultra/os/settimer.o(.bss);
        build/src/libultra/io/siacs.o(.bss);
        build/src/libultra/gu/sinf.o(.bss);
        build/src/libultra/io/sirawdma.o(.bss);
        build/src/libultra/io/si.o(.bss);
        build/src/libultra/io/sirawread.o(.bss);
        build/src/libultra/io/sirawwrite.o(.bss);
        build/src/libultra/libc/sprintf.o(.bss);
        build/src/libultra/io/sptask.o(.bss);
        build/asm/libultra/libc/bcopy.o(.bss);
        build/src/libultra/io/sp.o(.bss);
        build/src/libultra/io/sprawdma.o(.bss);
        build/src/libultra/io/spsetpc.o(.bss);
        build/src/libultra/io/spsetstat.o(.bss);
        build/src/libultra/io/sptaskyield.o(.bss);
        build/src/libultra/io/sptaskyielded.o(.bss);
        build/src/libultra/io/spgetstat.o(.bss);
        build/src/libultra/os/startthread.o(.bss);
        build/src/libultra/os/stopthread.o(.bss);
        build/src/libultra/libc/string.o(.bss);
        build/src/libultra/os/thread.o(.bss);
        build/src/libultra/os/timerintr.o(.bss);
        build/asm/libultra/os/setcompare.o(.bss);
        build/src/libultra/io/viblack.o(.bss);
        build/src/libultra/io/vi.o(.bss);
        build/src/libultra/io/vigetfield.o(.bss);
        build/src/libultra/io/vimgr.o(.bss);
        build/src/libultra/io/vigetcurrcontext.o(.bss);
        build/src/libultra/os/virtualtophysical.o(.bss);
        build/asm/libultra/os/probetlb.o(.bss);
        build/src/libultra/io/visetevent.o(.bss);
        build/src/libultra/io/visetmode.o(.bss);
        build/src/libultra/io/visetspecial.o(.bss);
        build/src/libultra/io/viswapbuf.o(.bss);
        build/src/libultra/io/viswapcontext.o(.bss);
        build/asm/libultra/os/writebackdcache.o(.bss);
        build/asm/libultra/os/writebackdcacheall.o(.bss);
        build/src/libultra/libc/xprintf.o(.bss);
        build/src/libultra/libc/xldtob.o(.bss);
        build/src/libultra/libc/ldiv.o(.bss);
        build/src/libultra/libc/xlitob.o(.bss);
        build/src/libultra/os/yieldthread.o(.bss);
        build/asm/main/3EB20.o(.bss);
        build/asm/main/3EBA0.o(.bss);
        build/asm/main/3F160.o(.bss);
        build/asm/main/40F10.o(.bss);
        build/asm/main/42AF0.o(.bss);
        build/asm/main/463D0.o(.bss);
        build/asm/main/47220.o(.bss);
        build/asm/main/4A300.o(.bss);
        build/asm/main/4D900.o(.bss);
        build/asm/main/544B0.o(.bss);
        build/asm/main/55250.o(.bss);
        build/asm/main/55AF0.o(.bss);
        build/asm/main/561F0.o(.bss);
        build/asm/main/562A0.o(.bss);
        build/asm/main/56630.o(.bss);
        build/asm/main/56F50.o(.bss);
        build/asm/main/5A750.o(.bss);
        build/asm/main/5AD20.o(.bss);
        build/asm/main/5D220.o(.bss);
        build/asm/main/5FA70.o(.bss);
        build/asm/main/61FC0.o(.bss);
        build/asm/main/64EA0.o(.bss);
        build/asm/main/65540.o(.bss);
        build/asm/main/66660.o(.bss);
        build/asm/main/66FB0.o(.bss);
        build/asm/main/68990.o(.bss);
        build/asm/main/6A6F0.o(.bss);
        build/asm/main/6B8B0.o(.bss);
        build/asm/main/6C310.o(.bss);
        build/asm/main/6E500.o(.bss);
        build/asm/main/700B0.o(.bss);
        build/asm/main/738F0.o(.bss);
        build/asm/main/79E80.o(.bss);
        build/asm/main/7A8E0.o(.bss);
        build/asm/main/7ACF0.o(.bss);
        build/asm/main/7B470.o(.bss);
        build/asm/main/7CEA0.o(.bss);
        build/asm/main/82E70.o(.bss);
        build/asm/data/main/rspbootText.o(.bss);
        build/asm/main/832A0.o(.bss);
        build/asm/main/94A80.o(.bss);
        build/asm/main/94F50.o(.bss);
        build/asm/main/97D20.o(.bss);
        build/asm/main/98960.o(.bss);
        build/asm/main/9A850.o(.bss);
        build/asm/data/main/aspMainText.o(.bss);
        build/asm/main/9BB60.o(.bss);
        build/asm/main/9CED0.o(.bss);
        build/asm/main/9E3D0.o(.bss);
        . = ALIGN(., 16);
        main_BSS_END = .;
        main_BSS_SIZE = ABSOLUTE(main_BSS_END - main_BSS_START);
    }
    __romPos += SIZEOF(.main);
    __romPos = ALIGN(__romPos, 16);
    . = ALIGN(., 16);
    main_ROM_END = __romPos;
    main_VRAM_END = .;

    mission_overlay_ROM_START = __romPos;
    mission_overlay_VRAM = ADDR(.mission_overlay);
    .mission_overlay 0x800A5130 : AT(mission_overlay_ROM_START) SUBALIGN(16)
    {
        FILL(0x00000000);
        mission_overlay_TEXT_START = .;
        build/asm/mission_overlay/0AA780.o(.text);
        build/asm/mission_overlay/0AB2D0.o(.text);
        build/asm/mission_overlay/0AB6E0.o(.text);
        build/asm/mission_overlay/0ADF80.o(.text);
        build/asm/mission_overlay/0AEFF0.o(.text);
        build/asm/mission_overlay/0B4EC0.o(.text);
        build/asm/mission_overlay/0B64C0.o(.text);
        build/asm/mission_overlay/0B81D0.o(.text);
        build/asm/mission_overlay/0B9600.o(.text);
        build/asm/mission_overlay/0BAFF0.o(.text);
        build/asm/mission_overlay/0BC930.o(.text);
        build/asm/mission_overlay/0BD840.o(.text);
        build/asm/mission_overlay/0BE650.o(.text);
        build/asm/mission_overlay/0BF800.o(.text);
        build/asm/mission_overlay/0C00A0.o(.text);
        build/asm/mission_overlay/0C0390.o(.text);
        build/asm/mission_overlay/0C4DB0.o(.text);
        build/asm/mission_overlay/0C70B0.o(.text);
        build/asm/mission_overlay/0C89C0.o(.text);
        build/asm/mission_overlay/0CAE70.o(.text);
        build/asm/mission_overlay/0CC9A0.o(.text);
        build/asm/mission_overlay/0CFB20.o(.text);
        build/asm/mission_overlay/0D38A0.o(.text);
        build/asm/mission_overlay/0D5AD0.o(.text);
        build/asm/mission_overlay/0D6BE0.o(.text);
        build/asm/mission_overlay/0D8450.o(.text);
        build/asm/mission_overlay/0DCF00.o(.text);
        build/asm/mission_overlay/0DDED0.o(.text);
        build/asm/mission_overlay/0E0790.o(.text);
        build/asm/mission_overlay/0E4C70.o(.text);
        build/asm/mission_overlay/0E5080.o(.text);
        build/asm/mission_overlay/0E7DD0.o(.text);
        build/asm/mission_overlay/0E9640.o(.text);
        build/asm/mission_overlay/0EA6E0.o(.text);
        build/asm/mission_overlay/0ECD10.o(.text);
        build/asm/mission_overlay/0ED2F0.o(.text);
        build/asm/mission_overlay/0EDA10.o(.text);
        build/asm/mission_overlay/0EDD50.o(.text);
        build/asm/mission_overlay/0F0980.o(.text);
        build/asm/mission_overlay/0F09E0.o(.text);
        build/asm/mission_overlay/0F3E90.o(.text);
        build/asm/mission_overlay/0FAE50.o(.text);
        build/asm/mission_overlay/0FCA20.o(.text);
        build/asm/mission_overlay/0FFB10.o(.text);
        build/asm/mission_overlay/level_objective_handling/lv_0.o(.text);
        build/asm/mission_overlay/level_objective_handling/lv_1.o(.text);
        build/asm/mission_overlay/level_objective_handling/lv_2.o(.text);
        build/asm/mission_overlay/level_objective_handling/lv_3.o(.text);
        build/asm/mission_overlay/level_objective_handling/lv_4.o(.text);
        build/asm/mission_overlay/level_objective_handling/lv_5.o(.text);
        build/asm/mission_overlay/level_objective_handling/lv_6.o(.text);
        build/asm/mission_overlay/level_objective_handling/lv_7.o(.text);
        build/asm/mission_overlay/level_objective_handling/lv_8.o(.text);
        build/asm/mission_overlay/level_objective_handling/lv_9.o(.text);
        build/asm/mission_overlay/level_objective_handling/lv_a.o(.text);
        build/asm/mission_overlay/level_objective_handling/lv_b.o(.text);
        build/asm/mission_overlay/level_objective_handling/lv_c.o(.text);
        build/asm/mission_overlay/level_objective_handling/lv_d.o(.text);
        build/asm/mission_overlay/level_objective_handling/lv_e.o(.text);
        build/asm/mission_overlay/level_objective_handling/lv_f.o(.text);
        build/asm/mission_overlay/level_objective_handling/lv_g.o(.text);
        build/asm/mission_overlay/level_objective_handling/lv_h.o(.text);
        build/asm/mission_overlay/level_objective_handling/lv_i.o(.text);
        build/asm/mission_overlay/level_objective_handling/lv_k.o(.text);
        build/asm/mission_overlay/level_objective_handling/lv_j.o(.text);
        . = ALIGN(., 16);
        mission_overlay_TEXT_END = .;
        mission_overlay_TEXT_SIZE = ABSOLUTE(mission_overlay_TEXT_END - mission_overlay_TEXT_START);
        mission_overlay_DATA_START = .;
        build/asm/mission_overlay/0AA780.o(.data);
        build/asm/mission_overlay/0AB2D0.o(.data);
        build/asm/mission_overlay/0AB6E0.o(.data);
        build/asm/mission_overlay/0ADF80.o(.data);
        build/asm/mission_overlay/0AEFF0.o(.data);
        build/asm/mission_overlay/0B4EC0.o(.data);
        build/asm/mission_overlay/0B64C0.o(.data);
        build/asm/mission_overlay/0B81D0.o(.data);
        build/asm/mission_overlay/0B9600.o(.data);
        build/asm/mission_overlay/0BAFF0.o(.data);
        build/asm/mission_overlay/0BC930.o(.data);
        build/asm/mission_overlay/0BD840.o(.data);
        build/asm/mission_overlay/0BE650.o(.data);
        build/asm/mission_overlay/0BF800.o(.data);
        build/asm/mission_overlay/0C00A0.o(.data);
        build/asm/mission_overlay/0C0390.o(.data);
        build/asm/mission_overlay/0C4DB0.o(.data);
        build/asm/mission_overlay/0C70B0.o(.data);
        build/asm/mission_overlay/0C89C0.o(.data);
        build/asm/mission_overlay/0CAE70.o(.data);
        build/asm/mission_overlay/0CC9A0.o(.data);
        build/asm/mission_overlay/0CFB20.o(.data);
        build/asm/mission_overlay/0D38A0.o(.data);
        build/asm/mission_overlay/0D5AD0.o(.data);
        build/asm/mission_overlay/0D6BE0.o(.data);
        build/asm/mission_overlay/0D8450.o(.data);
        build/asm/mission_overlay/0DCF00.o(.data);
        build/asm/mission_overlay/0DDED0.o(.data);
        build/asm/mission_overlay/0E0790.o(.data);
        build/asm/mission_overlay/0E4C70.o(.data);
        build/asm/mission_overlay/0E5080.o(.data);
        build/asm/mission_overlay/0E7DD0.o(.data);
        build/asm/mission_overlay/0E9640.o(.data);
        build/asm/mission_overlay/0EA6E0.o(.data);
        build/asm/mission_overlay/0ECD10.o(.data);
        build/asm/mission_overlay/0ED2F0.o(.data);
        build/asm/mission_overlay/0EDA10.o(.data);
        build/asm/mission_overlay/0EDD50.o(.data);
        build/asm/mission_overlay/0F0980.o(.data);
        build/asm/mission_overlay/0F09E0.o(.data);
        build/asm/mission_overlay/0F3E90.o(.data);
        build/asm/mission_overlay/0FAE50.o(.data);
        build/asm/mission_overlay/0FCA20.o(.data);
        build/asm/mission_overlay/0FFB10.o(.data);
        build/asm/mission_overlay/level_objective_handling/lv_0.o(.data);
        build/asm/mission_overlay/level_objective_handling/lv_1.o(.data);
        build/asm/mission_overlay/level_objective_handling/lv_2.o(.data);
        build/asm/mission_overlay/level_objective_handling/lv_3.o(.data);
        build/asm/mission_overlay/level_objective_handling/lv_4.o(.data);
        build/asm/mission_overlay/level_objective_handling/lv_5.o(.data);
        build/asm/mission_overlay/level_objective_handling/lv_6.o(.data);
        build/asm/mission_overlay/level_objective_handling/lv_7.o(.data);
        build/asm/mission_overlay/level_objective_handling/lv_8.o(.data);
        build/asm/mission_overlay/level_objective_handling/lv_9.o(.data);
        build/asm/mission_overlay/level_objective_handling/lv_a.o(.data);
        build/asm/mission_overlay/level_objective_handling/lv_b.o(.data);
        build/asm/mission_overlay/level_objective_handling/lv_c.o(.data);
        build/asm/mission_overlay/level_objective_handling/lv_d.o(.data);
        build/asm/mission_overlay/level_objective_handling/lv_e.o(.data);
        build/asm/mission_overlay/level_objective_handling/lv_f.o(.data);
        build/asm/mission_overlay/level_objective_handling/lv_g.o(.data);
        build/asm/mission_overlay/level_objective_handling/lv_h.o(.data);
        build/asm/mission_overlay/level_objective_handling/lv_i.o(.data);
        build/asm/mission_overlay/level_objective_handling/lv_k.o(.data);
        build/asm/mission_overlay/level_objective_handling/lv_j.o(.data);
        build/asm/data/mission_overlay/10A240.data.o(.data);
        build/asm/data/mission_overlay/10A270.data.o(.data);
        build/asm/data/mission_overlay/10A280.data.o(.data);
        build/asm/data/mission_overlay/10A330.data.o(.data);
        build/asm/data/mission_overlay/10A400.data.o(.data);
        build/asm/data/mission_overlay/10A4B0.data.o(.data);
        build/asm/data/mission_overlay/10A520.data.o(.data);
        build/asm/data/mission_overlay/10A590.data.o(.data);
        build/asm/data/mission_overlay/10A5B0.data.o(.data);
        build/asm/data/mission_overlay/10A600.data.o(.data);
        build/asm/data/mission_overlay/10A660.data.o(.data);
        build/asm/data/mission_overlay/10A6D0.data.o(.data);
        build/asm/data/mission_overlay/10A700.data.o(.data);
        build/asm/data/mission_overlay/10A980.data.o(.data);
        build/asm/data/mission_overlay/10ABE0.data.o(.data);
        build/asm/data/mission_overlay/10AC90.data.o(.data);
        build/asm/data/mission_overlay/10B050.data.o(.data);
        build/asm/data/mission_overlay/10B200.data.o(.data);
        build/asm/data/mission_overlay/10B210.data.o(.data);
        build/asm/data/mission_overlay/10B450.data.o(.data);
        build/asm/data/mission_overlay/10B480.data.o(.data);
        build/asm/data/mission_overlay/10B4B0.data.o(.data);
        build/asm/data/mission_overlay/10B550.data.o(.data);
        build/asm/data/mission_overlay/10B560.data.o(.data);
        build/asm/data/mission_overlay/10B700.data.o(.data);
        build/asm/data/mission_overlay/10B890.data.o(.data);
        build/asm/data/mission_overlay/10BBB0.data.o(.data);
        build/asm/data/mission_overlay/10BCD0.data.o(.data);
        build/asm/data/mission_overlay/10BD60.data.o(.data);
        build/asm/data/mission_overlay/10BF20.data.o(.data);
        build/asm/data/mission_overlay/10BFA0.data.o(.data);
        build/asm/data/mission_overlay/10BFF0.data.o(.data);
        build/asm/data/mission_overlay/10C0C0.data.o(.data);
        build/asm/data/mission_overlay/10C0E0.data.o(.data);
        build/asm/data/mission_overlay/10C110.data.o(.data);
        build/asm/data/mission_overlay/10C290.data.o(.data);
        build/asm/data/mission_overlay/10C2B0.data.o(.data);
        build/asm/data/mission_overlay/10C2C0.data.o(.data);
        . = ALIGN(., 16);
        mission_overlay_DATA_END = .;
        mission_overlay_DATA_SIZE = ABSOLUTE(mission_overlay_DATA_END - mission_overlay_DATA_START);
        mission_overlay_RODATA_START = .;
        build/asm/data/mission_overlay/0A5D30.rodata.o(.rodata);
        build/asm/data/mission_overlay/0A5DE0.rodata.o(.rodata);
        build/asm/data/mission_overlay/0A5DF0.rodata.o(.rodata);
        build/asm/data/mission_overlay/0A5FE0.rodata.o(.rodata);
        build/asm/data/mission_overlay/0A6420.rodata.o(.rodata);
        build/asm/data/mission_overlay/0A6590.rodata.o(.rodata);
        build/asm/data/mission_overlay/0A6720.rodata.o(.rodata);
        build/asm/data/mission_overlay/0A6820.rodata.o(.rodata);
        build/asm/data/mission_overlay/0A6AE0.rodata.o(.rodata);
        build/asm/data/mission_overlay/0A6BE0.rodata.o(.rodata);
        build/asm/data/mission_overlay/0A6CD0.rodata.o(.rodata);
        build/asm/data/mission_overlay/0A6DE0.rodata.o(.rodata);
        build/asm/data/mission_overlay/0A6E40.rodata.o(.rodata);
        build/asm/data/mission_overlay/0A6E50.rodata.o(.rodata);
        build/asm/data/mission_overlay/0A7330.rodata.o(.rodata);
        build/asm/data/mission_overlay/0A7480.rodata.o(.rodata);
        build/asm/data/mission_overlay/0A7560.rodata.o(.rodata);
        build/asm/data/mission_overlay/0A7570.rodata.o(.rodata);
        build/asm/data/mission_overlay/0A7780.rodata.o(.rodata);
        build/asm/data/mission_overlay/0A77A0.rodata.o(.rodata);
        build/asm/data/mission_overlay/0A7FC0.rodata.o(.rodata);
        build/asm/data/mission_overlay/0A81F0.rodata.o(.rodata);
        build/asm/data/mission_overlay/0A8290.rodata.o(.rodata);
        build/asm/data/mission_overlay/0A8560.rodata.o(.rodata);
        build/asm/data/mission_overlay/0A8710.rodata.o(.rodata);
        build/asm/data/mission_overlay/0A8910.rodata.o(.rodata);
        build/asm/data/mission_overlay/0A89E0.rodata.o(.rodata);
        build/asm/data/mission_overlay/0A8E90.rodata.o(.rodata);
        build/asm/data/mission_overlay/0A90C0.rodata.o(.rodata);
        build/asm/data/mission_overlay/0A92D0.rodata.o(.rodata);
        build/asm/data/mission_overlay/0A9490.rodata.o(.rodata);
        build/asm/data/mission_overlay/0A9530.rodata.o(.rodata);
        build/asm/data/mission_overlay/0A9570.rodata.o(.rodata);
        build/asm/data/mission_overlay/0A9B70.rodata.o(.rodata);
        build/asm/data/mission_overlay/0A9CB0.rodata.o(.rodata);
        build/asm/data/mission_overlay/0AA030.rodata.o(.rodata);
        build/asm/data/mission_overlay/0AA0D0.rodata.o(.rodata);
        build/asm/data/mission_overlay/0AA150.rodata.o(.rodata);
        build/asm/data/mission_overlay/0AA190.rodata.o(.rodata);
        build/asm/data/mission_overlay/0AA1B0.rodata.o(.rodata);
        build/asm/data/mission_overlay/0AA220.rodata.o(.rodata);
        build/asm/data/mission_overlay/0AA2C0.rodata.o(.rodata);
        build/asm/data/mission_overlay/0AA330.rodata.o(.rodata);
        build/asm/data/mission_overlay/0AA360.rodata.o(.rodata);
        build/asm/data/mission_overlay/0AA380.rodata.o(.rodata);
        build/asm/data/mission_overlay/0AA3D0.rodata.o(.rodata);
        build/asm/data/mission_overlay/0AA430.rodata.o(.rodata);
        build/asm/data/mission_overlay/0AA460.rodata.o(.rodata);
        build/asm/data/mission_overlay/0AA470.rodata.o(.rodata);
        build/asm/data/mission_overlay/0AA4F0.rodata.o(.rodata);
        build/asm/data/mission_overlay/0AA570.rodata.o(.rodata);
        build/asm/data/mission_overlay/0AA5A0.rodata.o(.rodata);
        build/asm/data/mission_overlay/0AA5F0.rodata.o(.rodata);
        build/asm/data/mission_overlay/0AA640.rodata.o(.rodata);
        build/asm/data/mission_overlay/0AA680.rodata.o(.rodata);
        build/asm/data/mission_overlay/0AA760.rodata.o(.rodata);
        build/asm/mission_overlay/0AA780.o(.rodata);
        build/asm/mission_overlay/0AB2D0.o(.rodata);
        build/asm/mission_overlay/0AB6E0.o(.rodata);
        build/asm/mission_overlay/0ADF80.o(.rodata);
        build/asm/mission_overlay/0AEFF0.o(.rodata);
        build/asm/mission_overlay/0B4EC0.o(.rodata);
        build/asm/mission_overlay/0B64C0.o(.rodata);
        build/asm/mission_overlay/0B81D0.o(.rodata);
        build/asm/mission_overlay/0B9600.o(.rodata);
        build/asm/mission_overlay/0BAFF0.o(.rodata);
        build/asm/mission_overlay/0BC930.o(.rodata);
        build/asm/mission_overlay/0BD840.o(.rodata);
        build/asm/mission_overlay/0BE650.o(.rodata);
        build/asm/mission_overlay/0BF800.o(.rodata);
        build/asm/mission_overlay/0C00A0.o(.rodata);
        build/asm/mission_overlay/0C0390.o(.rodata);
        build/asm/mission_overlay/0C4DB0.o(.rodata);
        build/asm/mission_overlay/0C70B0.o(.rodata);
        build/asm/mission_overlay/0C89C0.o(.rodata);
        build/asm/mission_overlay/0CAE70.o(.rodata);
        build/asm/mission_overlay/0CC9A0.o(.rodata);
        build/asm/mission_overlay/0CFB20.o(.rodata);
        build/asm/mission_overlay/0D38A0.o(.rodata);
        build/asm/mission_overlay/0D5AD0.o(.rodata);
        build/asm/mission_overlay/0D6BE0.o(.rodata);
        build/asm/mission_overlay/0D8450.o(.rodata);
        build/asm/mission_overlay/0DCF00.o(.rodata);
        build/asm/mission_overlay/0DDED0.o(.rodata);
        build/asm/mission_overlay/0E0790.o(.rodata);
        build/asm/mission_overlay/0E4C70.o(.rodata);
        build/asm/mission_overlay/0E5080.o(.rodata);
        build/asm/mission_overlay/0E7DD0.o(.rodata);
        build/asm/mission_overlay/0E9640.o(.rodata);
        build/asm/mission_overlay/0EA6E0.o(.rodata);
        build/asm/mission_overlay/0ECD10.o(.rodata);
        build/asm/mission_overlay/0ED2F0.o(.rodata);
        build/asm/mission_overlay/0EDA10.o(.rodata);
        build/asm/mission_overlay/0EDD50.o(.rodata);
        build/asm/mission_overlay/0F0980.o(.rodata);
        build/asm/mission_overlay/0F09E0.o(.rodata);
        build/asm/mission_overlay/0F3E90.o(.rodata);
        build/asm/mission_overlay/0FAE50.o(.rodata);
        build/asm/mission_overlay/0FCA20.o(.rodata);
        build/asm/mission_overlay/0FFB10.o(.rodata);
        build/asm/mission_overlay/level_objective_handling/lv_0.o(.rodata);
        build/asm/mission_overlay/level_objective_handling/lv_1.o(.rodata);
        build/asm/mission_overlay/level_objective_handling/lv_2.o(.rodata);
        build/asm/mission_overlay/level_objective_handling/lv_3.o(.rodata);
        build/asm/mission_overlay/level_objective_handling/lv_4.o(.rodata);
        build/asm/mission_overlay/level_objective_handling/lv_5.o(.rodata);
        build/asm/mission_overlay/level_objective_handling/lv_6.o(.rodata);
        build/asm/mission_overlay/level_objective_handling/lv_7.o(.rodata);
        build/asm/mission_overlay/level_objective_handling/lv_8.o(.rodata);
        build/asm/mission_overlay/level_objective_handling/lv_9.o(.rodata);
        build/asm/mission_overlay/level_objective_handling/lv_a.o(.rodata);
        build/asm/mission_overlay/level_objective_handling/lv_b.o(.rodata);
        build/asm/mission_overlay/level_objective_handling/lv_c.o(.rodata);
        build/asm/mission_overlay/level_objective_handling/lv_d.o(.rodata);
        build/asm/mission_overlay/level_objective_handling/lv_e.o(.rodata);
        build/asm/mission_overlay/level_objective_handling/lv_f.o(.rodata);
        build/asm/mission_overlay/level_objective_handling/lv_g.o(.rodata);
        build/asm/mission_overlay/level_objective_handling/lv_h.o(.rodata);
        build/asm/mission_overlay/level_objective_handling/lv_i.o(.rodata);
        build/asm/mission_overlay/level_objective_handling/lv_k.o(.rodata);
        build/asm/mission_overlay/level_objective_handling/lv_j.o(.rodata);
        . = ALIGN(., 16);
        mission_overlay_RODATA_END = .;
        mission_overlay_RODATA_SIZE = ABSOLUTE(mission_overlay_RODATA_END - mission_overlay_RODATA_START);
    }
    mission_overlay_bss_VRAM = ADDR(.mission_overlay_bss);
    .mission_overlay_bss (NOLOAD) : SUBALIGN(16)
    {
        FILL(0x00000000);
        mission_overlay_BSS_START = .;
        build/asm/mission_overlay/0AA780.o(.bss);
        build/asm/mission_overlay/0AB2D0.o(.bss);
        build/asm/mission_overlay/0AB6E0.o(.bss);
        build/asm/mission_overlay/0ADF80.o(.bss);
        build/asm/mission_overlay/0AEFF0.o(.bss);
        build/asm/mission_overlay/0B4EC0.o(.bss);
        build/asm/mission_overlay/0B64C0.o(.bss);
        build/asm/mission_overlay/0B81D0.o(.bss);
        build/asm/mission_overlay/0B9600.o(.bss);
        build/asm/mission_overlay/0BAFF0.o(.bss);
        build/asm/mission_overlay/0BC930.o(.bss);
        build/asm/mission_overlay/0BD840.o(.bss);
        build/asm/mission_overlay/0BE650.o(.bss);
        build/asm/mission_overlay/0BF800.o(.bss);
        build/asm/mission_overlay/0C00A0.o(.bss);
        build/asm/mission_overlay/0C0390.o(.bss);
        build/asm/mission_overlay/0C4DB0.o(.bss);
        build/asm/mission_overlay/0C70B0.o(.bss);
        build/asm/mission_overlay/0C89C0.o(.bss);
        build/asm/mission_overlay/0CAE70.o(.bss);
        build/asm/mission_overlay/0CC9A0.o(.bss);
        build/asm/mission_overlay/0CFB20.o(.bss);
        build/asm/mission_overlay/0D38A0.o(.bss);
        build/asm/mission_overlay/0D5AD0.o(.bss);
        build/asm/mission_overlay/0D6BE0.o(.bss);
        build/asm/mission_overlay/0D8450.o(.bss);
        build/asm/mission_overlay/0DCF00.o(.bss);
        build/asm/mission_overlay/0DDED0.o(.bss);
        build/asm/mission_overlay/0E0790.o(.bss);
        build/asm/mission_overlay/0E4C70.o(.bss);
        build/asm/mission_overlay/0E5080.o(.bss);
        build/asm/mission_overlay/0E7DD0.o(.bss);
        build/asm/mission_overlay/0E9640.o(.bss);
        build/asm/mission_overlay/0EA6E0.o(.bss);
        build/asm/mission_overlay/0ECD10.o(.bss);
        build/asm/mission_overlay/0ED2F0.o(.bss);
        build/asm/mission_overlay/0EDA10.o(.bss);
        build/asm/mission_overlay/0EDD50.o(.bss);
        build/asm/mission_overlay/0F0980.o(.bss);
        build/asm/mission_overlay/0F09E0.o(.bss);
        build/asm/mission_overlay/0F3E90.o(.bss);
        build/asm/mission_overlay/0FAE50.o(.bss);
        build/asm/mission_overlay/0FCA20.o(.bss);
        build/asm/mission_overlay/0FFB10.o(.bss);
        build/asm/mission_overlay/level_objective_handling/lv_0.o(.bss);
        build/asm/mission_overlay/level_objective_handling/lv_1.o(.bss);
        build/asm/mission_overlay/level_objective_handling/lv_2.o(.bss);
        build/asm/mission_overlay/level_objective_handling/lv_3.o(.bss);
        build/asm/mission_overlay/level_objective_handling/lv_4.o(.bss);
        build/asm/mission_overlay/level_objective_handling/lv_5.o(.bss);
        build/asm/mission_overlay/level_objective_handling/lv_6.o(.bss);
        build/asm/mission_overlay/level_objective_handling/lv_7.o(.bss);
        build/asm/mission_overlay/level_objective_handling/lv_8.o(.bss);
        build/asm/mission_overlay/level_objective_handling/lv_9.o(.bss);
        build/asm/mission_overlay/level_objective_handling/lv_a.o(.bss);
        build/asm/mission_overlay/level_objective_handling/lv_b.o(.bss);
        build/asm/mission_overlay/level_objective_handling/lv_c.o(.bss);
        build/asm/mission_overlay/level_objective_handling/lv_d.o(.bss);
        build/asm/mission_overlay/level_objective_handling/lv_e.o(.bss);
        build/asm/mission_overlay/level_objective_handling/lv_f.o(.bss);
        build/asm/mission_overlay/level_objective_handling/lv_g.o(.bss);
        build/asm/mission_overlay/level_objective_handling/lv_h.o(.bss);
        build/asm/mission_overlay/level_objective_handling/lv_i.o(.bss);
        build/asm/mission_overlay/level_objective_handling/lv_k.o(.bss);
        build/asm/mission_overlay/level_objective_handling/lv_j.o(.bss);
        build/asm/data/mission_overlay/8010B6D0.bss.o(.bss);
        . = ALIGN(., 16);
        mission_overlay_BSS_END = .;
        mission_overlay_BSS_SIZE = ABSOLUTE(mission_overlay_BSS_END - mission_overlay_BSS_START);
    }
    __romPos += SIZEOF(.mission_overlay);
    __romPos = ALIGN(__romPos, 16);
    . = ALIGN(., 16);
    mission_overlay_ROM_END = __romPos;
    mission_overlay_VRAM_END = .;

    menu_overlay_ROM_START = __romPos;
    menu_overlay_VRAM = ADDR(.menu_overlay);
    .menu_overlay 0x800A5130 : AT(menu_overlay_ROM_START) SUBALIGN(16)
    {
        FILL(0x00000000);
        menu_overlay_TEXT_START = .;
        build/asm/menu_overlay/110410.o(.text);
        build/asm/menu_overlay/115E00.o(.text);
        build/asm/menu_overlay/1197D0.o(.text);
        build/asm/menu_overlay/11B970.o(.text);
        build/asm/menu_overlay/12CA40.o(.text);
        build/asm/menu_overlay/jfif_handling.o(.text);
        build/asm/menu_overlay/intro_crawl_handling.o(.text);
        build/asm/menu_overlay/1331E0.o(.text);
        . = ALIGN(., 16);
        menu_overlay_TEXT_END = .;
        menu_overlay_TEXT_SIZE = ABSOLUTE(menu_overlay_TEXT_END - menu_overlay_TEXT_START);
        menu_overlay_DATA_START = .;
        build/asm/menu_overlay/110410.o(.data);
        build/asm/menu_overlay/115E00.o(.data);
        build/asm/menu_overlay/1197D0.o(.data);
        build/asm/menu_overlay/11B970.o(.data);
        build/asm/menu_overlay/12CA40.o(.data);
        build/asm/menu_overlay/jfif_handling.o(.data);
        build/asm/menu_overlay/intro_crawl_handling.o(.data);
        build/asm/menu_overlay/1331E0.o(.data);
        build/asm/data/menu_overlay/133580.data.o(.data);
        build/asm/data/menu_overlay/133890.data.o(.data);
        build/asm/data/menu_overlay/1339F0.data.o(.data);
        build/asm/data/menu_overlay/133A10.data.o(.data);
        build/asm/data/menu_overlay/134450.data.o(.data);
        build/asm/data/menu_overlay/134610.data.o(.data);
        build/asm/data/menu_overlay/1346B0.data.o(.data);
        . = ALIGN(., 16);
        menu_overlay_DATA_END = .;
        menu_overlay_DATA_SIZE = ABSOLUTE(menu_overlay_DATA_END - menu_overlay_DATA_START);
        menu_overlay_RODATA_START = .;
        build/asm/data/menu_overlay/10C2D0.rodata.o(.rodata);
        build/asm/data/menu_overlay/10CA10.rodata.o(.rodata);
        build/asm/data/menu_overlay/10CB70.rodata.o(.rodata);
        build/asm/data/menu_overlay/10CDC0.rodata.o(.rodata);
        build/asm/data/menu_overlay/10CE50.rodata.o(.rodata);
        build/asm/data/menu_overlay/10CF70.rodata.o(.rodata);
        build/asm/data/menu_overlay/10E700.rodata.o(.rodata);
        build/asm/data/menu_overlay/10E880.rodata.o(.rodata);
        build/asm/data/menu_overlay/10EA50.rodata.o(.rodata);
        build/asm/data/menu_overlay/10ED70.rodata.o(.rodata);
        build/asm/data/menu_overlay/10ED80.rodata.o(.rodata);
        build/asm/data/menu_overlay/10EDA0.rodata.o(.rodata);
        build/asm/menu_overlay/110410.o(.rodata);
        build/asm/menu_overlay/115E00.o(.rodata);
        build/asm/menu_overlay/1197D0.o(.rodata);
        build/asm/menu_overlay/11B970.o(.rodata);
        build/asm/menu_overlay/12CA40.o(.rodata);
        build/asm/menu_overlay/jfif_handling.o(.rodata);
        build/asm/menu_overlay/intro_crawl_handling.o(.rodata);
        build/asm/menu_overlay/1331E0.o(.rodata);
        . = ALIGN(., 16);
        menu_overlay_RODATA_END = .;
        menu_overlay_RODATA_SIZE = ABSOLUTE(menu_overlay_RODATA_END - menu_overlay_RODATA_START);
    }
    menu_overlay_bss_VRAM = ADDR(.menu_overlay_bss);
    .menu_overlay_bss (NOLOAD) : SUBALIGN(16)
    {
        FILL(0x00000000);
        menu_overlay_BSS_START = .;
        build/asm/menu_overlay/110410.o(.bss);
        build/asm/menu_overlay/115E00.o(.bss);
        build/asm/menu_overlay/1197D0.o(.bss);
        build/asm/menu_overlay/11B970.o(.bss);
        build/asm/menu_overlay/12CA40.o(.bss);
        build/asm/menu_overlay/jfif_handling.o(.bss);
        build/asm/menu_overlay/intro_crawl_handling.o(.bss);
        build/asm/menu_overlay/1331E0.o(.bss);
        build/asm/data/menu_overlay/800CD520.bss.o(.bss);
        build/asm/data/menu_overlay/800CDCF0.bss.o(.bss);
        build/asm/data/menu_overlay/800CDD80.bss.o(.bss);
        . = ALIGN(., 16);
        menu_overlay_BSS_END = .;
        menu_overlay_BSS_SIZE = ABSOLUTE(menu_overlay_BSS_END - menu_overlay_BSS_START);
    }
    __romPos += SIZEOF(.menu_overlay);
    __romPos = ALIGN(__romPos, 16);
    . = ALIGN(., 16);
    menu_overlay_ROM_END = __romPos;
    menu_overlay_VRAM_END = .;

    _1346C0_ROM_START = __romPos;
    _1346C0_VRAM = ADDR(._1346C0);
    ._1346C0 : AT(_1346C0_ROM_START) SUBALIGN(16)
    {
        FILL(0x00000000);
        _1346C0_DATA_START = .;
        build/assets/1346C0.o(.data);
        _1346C0_DATA_END = .;
        _1346C0_DATA_SIZE = ABSOLUTE(_1346C0_DATA_END - _1346C0_DATA_START);
    }
    __romPos += SIZEOF(._1346C0);
    _1346C0_ROM_END = __romPos;
    _1346C0_VRAM_END = .;

    cinematic_overlay_ROM_START = __romPos;
    cinematic_overlay_VRAM = ADDR(.cinematic_overlay);
    .cinematic_overlay 0x800A5130 : AT(cinematic_overlay_ROM_START) SUBALIGN(16)
    {
        FILL(0x00000000);
        cinematic_overlay_TEXT_START = .;
        build/asm/cinematic_overlay/1381D0.o(.text);
        . = ALIGN(., 16);
        cinematic_overlay_TEXT_END = .;
        cinematic_overlay_TEXT_SIZE = ABSOLUTE(cinematic_overlay_TEXT_END - cinematic_overlay_TEXT_START);
        cinematic_overlay_DATA_START = .;
        build/asm/cinematic_overlay/1381D0.o(.data);
        build/asm/data/cinematic_overlay/141B00.data.o(.data);
        . = ALIGN(., 16);
        cinematic_overlay_DATA_END = .;
        cinematic_overlay_DATA_SIZE = ABSOLUTE(cinematic_overlay_DATA_END - cinematic_overlay_DATA_START);
        cinematic_overlay_RODATA_START = .;
        build/asm/data/cinematic_overlay/137580.rodata.o(.rodata);
        build/asm/data/cinematic_overlay/138030.rodata.o(.rodata);
        build/asm/cinematic_overlay/1381D0.o(.rodata);
        . = ALIGN(., 16);
        cinematic_overlay_RODATA_END = .;
        cinematic_overlay_RODATA_SIZE = ABSOLUTE(cinematic_overlay_RODATA_END - cinematic_overlay_RODATA_START);
    }
    cinematic_overlay_bss_VRAM = ADDR(.cinematic_overlay_bss);
    .cinematic_overlay_bss (NOLOAD) : SUBALIGN(16)
    {
        FILL(0x00000000);
        cinematic_overlay_BSS_START = .;
        build/asm/cinematic_overlay/1381D0.o(.bss);
        build/asm/data/cinematic_overlay/800B0940.bss.o(.bss);
        . = ALIGN(., 16);
        cinematic_overlay_BSS_END = .;
        cinematic_overlay_BSS_SIZE = ABSOLUTE(cinematic_overlay_BSS_END - cinematic_overlay_BSS_START);
    }
    __romPos += SIZEOF(.cinematic_overlay);
    __romPos = ALIGN(__romPos, 16);
    . = ALIGN(., 16);
    cinematic_overlay_ROM_END = __romPos;
    cinematic_overlay_VRAM_END = .;

    _142D90_ROM_START = __romPos;
    _142D90_VRAM = ADDR(._142D90);
    ._142D90 : AT(_142D90_ROM_START) SUBALIGN(16)
    {
        FILL(0x00000000);
        _142D90_DATA_START = .;
        build/assets/142D90.o(.data);
        _142D90_DATA_END = .;
        _142D90_DATA_SIZE = ABSOLUTE(_142D90_DATA_END - _142D90_DATA_START);
    }
    __romPos += SIZEOF(._142D90);
    _142D90_ROM_END = __romPos;
    _142D90_VRAM_END = .;

    the_data_blob_ROM_START = __romPos;
    the_data_blob_VRAM = ADDR(.the_data_blob);
    .the_data_blob : AT(the_data_blob_ROM_START) SUBALIGN(16)
    {
        FILL(0x00000000);
        the_data_blob_DATA_START = .;
        build/assets/the_data_blob.o(.data);
        the_data_blob_DATA_END = .;
        the_data_blob_DATA_SIZE = ABSOLUTE(the_data_blob_DATA_END - the_data_blob_DATA_START);
    }
    __romPos += SIZEOF(.the_data_blob);
    the_data_blob_ROM_END = __romPos;
    the_data_blob_VRAM_END = .;

    main_bss_ROM_START = __romPos;
    main_bss_bss_VRAM = ADDR(.main_bss_bss);
    .main_bss_bss 0x8010D200 (NOLOAD) : SUBALIGN(16)
    {
        FILL(0x00000000);
        main_bss_BSS_START = .;
        build/asm/data/main/8010D200.bss.o(.bss);
        build/asm/data/main/801128D0.bss.o(.bss);
        build/asm/data/main/801128E0.bss.o(.bss);
        build/src/zlib/inftrees.o(.bss);
        build/src/libultra/io/conteepread.o(.bss);
        build/src/libultra/io/controller.o(.bss);
        build/src/libultra/os/initialize.o(.bss);
        build/src/libultra/debug/kdebugserver.o(.bss);
        build/src/libultra/io/leointerrupt.o(.bss);
        build/src/libultra/io/leodiskinit.o(.bss);
        build/src/libultra/io/motor.o(.bss);
        build/src/libultra/io/pfsisplug.o(.bss);
        build/src/libultra/io/pimgr.o(.bss);
        build/src/libultra/io/cartrominit.o(.bss);
        build/src/libultra/io/piacs.o(.bss);
        build/src/libultra/os/seteventmesg.o(.bss);
        build/src/libultra/io/siacs.o(.bss);
        build/src/libultra/io/sptask.o(.bss);
        build/src/libultra/os/timerintr.o(.bss);
        build/src/libultra/io/vimgr.o(.bss);
        build/asm/data/main/80130B10.bss.o(.bss);
        . = ALIGN(., 16);
        main_bss_BSS_END = .;
        main_bss_BSS_SIZE = ABSOLUTE(main_bss_BSS_END - main_bss_BSS_START);
    }
    __romPos = ALIGN(__romPos, 16);
    . = ALIGN(., 16);
    main_bss_ROM_END = __romPos;
    main_bss_VRAM_END = .;

    /DISCARD/ :
    {
        *(*);
    }
}
